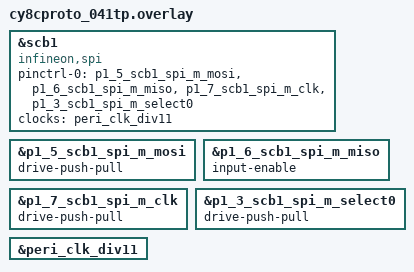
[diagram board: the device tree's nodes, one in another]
/*
 * SPDX-FileCopyrightText: <text>Copyright (c) 2026 Infineon Technologies AG,
 * or an affiliate of Infineon Technologies AG. All rights reserved.</text>
 *
 * SPDX-License-Identifier: Apache-2.0
 */

spi1: &scb1 {
	compatible = "infineon,spi";
	status = "okay";
	pinctrl-0 = <&p1_5_scb1_spi_m_mosi &p1_6_scb1_spi_m_miso
		     &p1_7_scb1_spi_m_clk &p1_3_scb1_spi_m_select0>;
	pinctrl-names = "default";
	clocks = <&peri_clk_div11>;
	#address-cells = <1>;
	#size-cells = <0>;
};

&p1_5_scb1_spi_m_mosi {
	drive-push-pull;
};

&p1_6_scb1_spi_m_miso {
	input-enable;
};

&p1_7_scb1_spi_m_clk {
	drive-push-pull;
};

&p1_3_scb1_spi_m_select0 {
	drive-push-pull;
};

&peri_clk_div11 {
	status = "okay";
};

#define SPI_LOOPBACK_SLOW_HZ 1000000
#define SPI_LOOPBACK_FAST_HZ 3000000

spi_loopback: &spi1 {
	status = "okay";
};

#include "../spi-loopback.dtsi"
